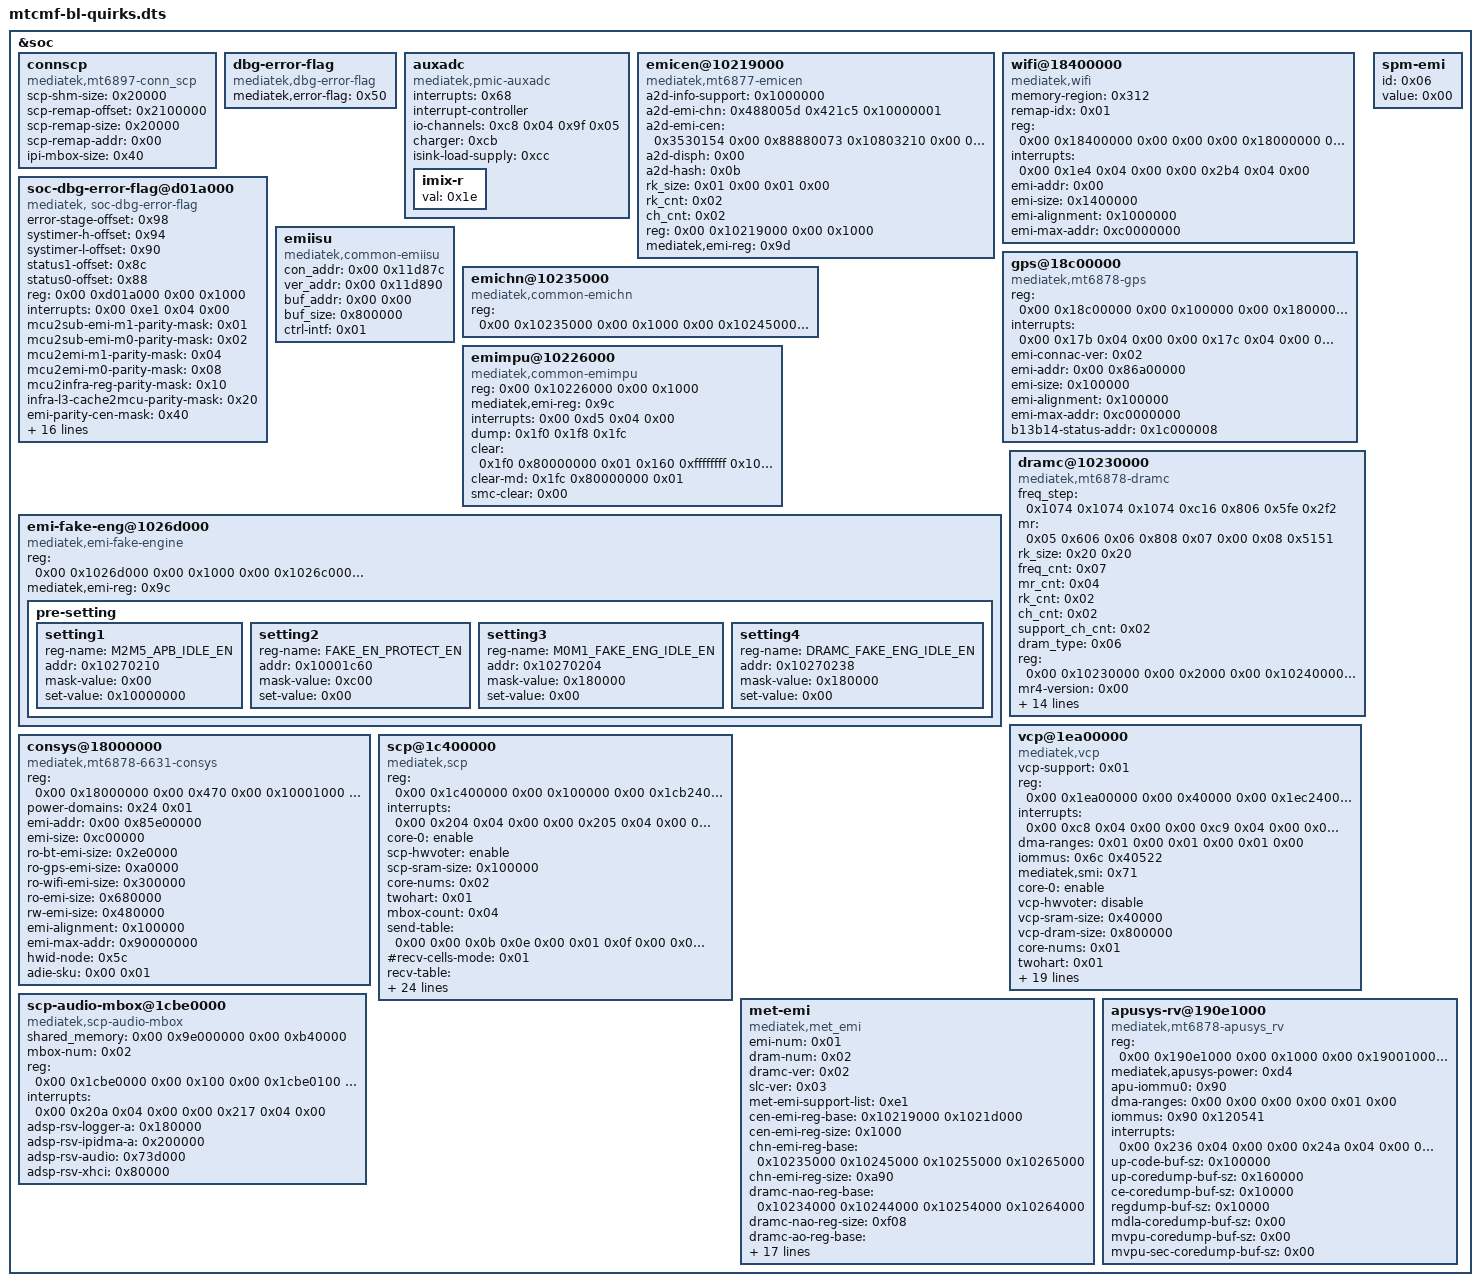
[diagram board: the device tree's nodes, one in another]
&soc {
        			connscp {
				compatible = "mediatek,mt6897-conn_scp";
				scp-shm-size = <0x20000>;
				scp-remap-offset = <0x2100000>;
				scp-remap-size = <0x20000>;
				scp-remap-addr = <0x00>;
				ipi-mbox-size = <0x40>;
				phandle = <0x26f>;
			};
			
			dbg-error-flag {
				compatible = "mediatek,dbg-error-flag";
				mediatek,error-flag = <0x50>;
			};
			
			auxadc {
				compatible = "mediatek,pmic-auxadc\0mediatek,mt6375-auxadc";
				interrupts = <0x68>;
				interrupt-controller;
				#interrupt-cells = <0x01>;
				#io-channel-cells = <0x01>;
				io-channels = <0xc8 0x04 0x9f 0x05>;
				io-channel-names = "chg_vbat\0auxadc_vbat";
				charger = <0xcb>;
				isink-load-supply = <0xcc>;
				phandle = <0x9f>;
				
				imix-r {
					val = <0x1e>;
				};
			};
			
			emicen@10219000 {
				a2d-info-support = <0x1000000>;
				a2d-emi-chn = <0x488005d 0x421c5 0x10000001>;
				a2d-emi-cen = <0x3530154 0x00 0x88880073 0x10803210 0x00 0x00>;
				a2d-disph = <0x00>;
				a2d-hash = <0x0b>;
				rk_size = <0x01 0x00 0x01 0x00>;
				rk_cnt = <0x02>;
				ch_cnt = <0x02>;
				compatible = "mediatek,mt6877-emicen";
				reg = <0x00 0x10219000 0x00 0x1000>;
				mediatek,emi-reg = <0x9d>;
				phandle = <0x9c>;
			};
			
			wifi@18400000 {
				memory-region = <0x312>;
				compatible = "mediatek,wifi";
				remap-idx = <0x01>;
				reg = <0x00 0x18400000 0x00 0x00 0x00 0x18000000 0x00 0x700000>;
				interrupts = <0x00 0x1e4 0x04 0x00 0x00 0x2b4 0x04 0x00>;
				emi-addr = <0x00>;
				emi-size = <0x1400000>;
				emi-alignment = <0x1000000>;
				emi-max-addr = <0xc0000000>;
				phandle = <0x28e>;
			};
			
			soc-dbg-error-flag@d01a000 {
				error-stage-offset = <0x98>;
				systimer-h-offset = <0x94>;
				systimer-l-offset = <0x90>;
				status1-offset = <0x8c>;
				status0-offset = <0x88>;
				compatible = "mediatek, soc-dbg-error-flag";
				reg = <0x00 0xd01a000 0x00 0x1000>;
				interrupts = <0x00 0xe1 0x04 0x00>;
				interrupt-names = "dbg-error-flag";
				mcu2sub-emi-m1-parity-mask = <0x01>;
				mcu2sub-emi-m0-parity-mask = <0x02>;
				mcu2emi-m1-parity-mask = <0x04>;
				mcu2emi-m0-parity-mask = <0x08>;
				mcu2infra-reg-parity-mask = <0x10>;
				infra-l3-cache2mcu-parity-mask = <0x20>;
				emi-parity-cen-mask = <0x40>;
				emi-parity-sub-cen-mask = <0x80>;
				emi-parity-chan1-mask = <0x100>;
				emi-parity-chan2-mask = <0x200>;
				emi-parity-chan3-mask = <0x400>;
				emi-parity-chan4-mask = <0x800>;
				dramc-error-flag-ch-a-mask = <0x1000>;
				dramc-error-flag-ch-b-mask = <0x2000>;
				dramc-error-flag-ch-c-mask = <0x4000>;
				dramc-error-flag-ch-d-mask = <0x8000>;
				ap-tracker-timeout-mask = <0x10000>;
				infra-tracker-timeout-mask = <0x20000>;
				infra-lastbus-timeout-mask = <0x1000000>;
				peri-lastbus-timeout-mask = <0x2000000>;
				dram-md32-wdt-event-ch-a-mask = <0x8000000>;
				dram-md32-wdt-event-ch-b-mask = <0x10000000>;
				dram-md32-wdt-event-ch-c-mask = <0x20000000>;
				phandle = <0x50>;
			};
			
			emiisu {
				con_addr = <0x00 0x11d87c>;
				ver_addr = <0x00 0x11d890>;
				buf_addr = <0x00 0x00>;
				buf_size = <0x800000>;
				compatible = "mediatek,common-emiisu";
				ctrl-intf = <0x01>;
			};
			gps@18c00000 {
				compatible = "mediatek,mt6878-gps";
				reg = <0x00 0x18c00000 0x00 0x100000 0x00 0x18000000 0x00 0x100000 0x00 0x1c000000 0x00 0x04 0x00 0x1c013058 0x00 0x04 0x00 0x1c013060 0x00 0x04 0x00 0x1c0130f8 0x00 0x28>;
				reg-names = "conn_gps_base\0conn_infra_base\0status_dummy_cr\0tia2_gps_on\0tia2_gps_rc_sel\0tia2_gps_debug";
				interrupts = <0x00 0x17b 0x04 0x00 0x00 0x17c 0x04 0x00 0x00 0x17d 0x04 0x00 0x00 0x17e 0x04 0x00 0x00 0x17f 0x04 0x00 0x00 0x185 0x04 0x00 0x00 0x81 0x04 0x00>;
				emi-connac-ver = <0x02>;
				emi-addr = <0x00 0x86a00000>;
				emi-size = <0x100000>;
				emi-alignment = <0x100000>;
				emi-max-addr = <0xc0000000>;
				b13b14-status-addr = <0x1c000008>;
				phandle = <0x249>;
			};
			
			
			emichn@10235000 {
				compatible = "mediatek,common-emichn";
				reg = <0x00 0x10235000 0x00 0x1000 0x00 0x10245000 0x00 0x1000>;
				phandle = <0x9d>;
			};
			
			emimpu@10226000 {
				compatible = "mediatek,common-emimpu";
				reg = <0x00 0x10226000 0x00 0x1000>;
				mediatek,emi-reg = <0x9c>;
				interrupts = <0x00 0xd5 0x04 0x00>;
				dump = <0x1f0 0x1f8 0x1fc>;
				clear = <0x1f0 0x80000000 0x01 0x160 0xffffffff 0x10 0x200 0x03 0x10>;
				clear-md = <0x1fc 0x80000000 0x01>;
				smc-clear = <0x00>;
				phandle = <0x1ca>;
			};
			emi-fake-eng@1026d000 {
				compatible = "mediatek,emi-fake-engine";
				reg = <0x00 0x1026d000 0x00 0x1000 0x00 0x1026c000 0x00 0x1000>;
				mediatek,emi-reg = <0x9c>;
				
				pre-setting {
					
					setting1 {
						reg-name = "M2M5_APB_IDLE_EN";
						addr = <0x10270210>;
						mask-value = <0x00>;
						set-value = <0x10000000>;
					};
					
					setting2 {
						reg-name = "FAKE_EN_PROTECT_EN";
						addr = <0x10001c60>;
						mask-value = <0xc00>;
						set-value = <0x00>;
					};
					
					setting3 {
						reg-name = "M0M1_FAKE_ENG_IDLE_EN";
						addr = <0x10270204>;
						mask-value = <0x180000>;
						set-value = <0x00>;
					};
					
					setting4 {
						reg-name = "DRAMC_FAKE_ENG_IDLE_EN";
						addr = <0x10270238>;
						mask-value = <0x180000>;
						set-value = <0x00>;
					};
				};
			};
			
			dramc@10230000 {
				freq_step = <0x1074 0x1074 0x1074 0xc16 0x806 0x5fe 0x2f2>;
				mr = <0x05 0x606 0x06 0x808 0x07 0x00 0x08 0x5151>;
				rk_size = <0x20 0x20>;
				freq_cnt = <0x07>;
				mr_cnt = <0x04>;
				rk_cnt = <0x02>;
				ch_cnt = <0x02>;
				support_ch_cnt = <0x02>;
				dram_type = <0x06>;
				compatible = "mediatek,mt6878-dramc\0mediatek,common-dramc";
				reg = <0x00 0x10230000 0x00 0x2000 0x00 0x10240000 0x00 0x2000 0x00 0x10234000 0x00 0x1000 0x00 0x10244000 0x00 0x1000 0x00 0x10238000 0x00 0x2000 0x00 0x10248000 0x00 0x2000 0x00 0x10236000 0x00 0x2000 0x00 0x10246000 0x00 0x2000 0x00 0x10006000 0x00 0x1000>;
				mr4-version = <0x00>;
				mr4-rg = <0x90 0xffff 0x00>;
				fmeter-version = <0x03>;
				use-real-freq = <0x01>;
				crystal-freq = <0x1a>;
				pll-id = <0xe98 0x2000000 0x19>;
				shu-lv = <0xe98 0xc000 0x0e>;
				shu-of = <0x700>;
				sdmpcw = <0x908 0x7fff8 0x03 0x928 0x7fff8 0x03>;
				posdiv = <0x90c 0x3800 0x0b 0x92c 0x3800 0x0b>;
				fbksel = <0x910 0x40 0x06 0x910 0x40 0x06>;
				dqsopen = <0xd94 0x4000000 0x1a 0xd94 0x4000000 0x1a>;
				async-ca = <0xd08 0x01 0x00 0xd08 0x01 0x00>;
				dq-ser-mode = <0xdc4 0x18 0x03 0xdc4 0x18 0x03>;
				phandle = <0x201>;
			};
			
			vcp@1ea00000 {
				#address-cells = <0x02>;
				#size-cells = <0x02>;
				compatible = "mediatek,vcp";
				vcp-support = <0x01>;
				status = "okay";
				reg = <0x00 0x1ea00000 0x00 0x40000 0x00 0x1ec24000 0x00 0x1000 0x00 0x1ec30000 0x00 0x1000 0x00 0x1ec32000 0x00 0x1000 0x00 0x1ec37000 0x00 0x1000 0x00 0x1ec40000 0x00 0x1000 0x00 0x1ec51000 0x00 0x1000 0x00 0x1ec52000 0x00 0x1000 0x00 0x1ec60000 0x00 0x40000 0x00 0x1eca5000 0x00 0x04 0x00 0x1e820000 0x00 0x04 0x00 0x1ecfb000 0x00 0x100 0x00 0x1ecfb100 0x00 0x04 0x00 0x1ecfb10c 0x00 0x04 0x00 0x1eca5020 0x00 0x04 0x00 0x1ecfc000 0x00 0x100 0x00 0x1ecfc100 0x00 0x04 0x00 0x1ecfc10c 0x00 0x04 0x00 0x1eca5024 0x00 0x04 0x00 0x1ecfd000 0x00 0x100 0x00 0x1ecfd100 0x00 0x04 0x00 0x1ecfd10c 0x00 0x04 0x00 0x1eca5028 0x00 0x04 0x00 0x1ecfe000 0x00 0x100 0x00 0x1ecfe100 0x00 0x04 0x00 0x1ecfe10c 0x00 0x04 0x00 0x1eca502c 0x00 0x04 0x00 0x1ecff000 0x00 0x100 0x00 0x1ecff100 0x00 0x04 0x00 0x1ecff10c 0x00 0x04 0x00 0x1eca5030 0x00 0x04>;
				reg-names = "vcp_sram_base\0vcp_cfgreg\0vcp_cfgreg_core0\0vcp_intc_core0\0vcp_pwr_ctl\0vcp_cfgreg_core1\0vcp_bus_debug\0vcp_bus_tracker\0vcp_l1creg\0vcp_cfgreg_sec\0vcp_cfgreg_mmu\0mbox0_base\0mbox0_set\0mbox0_clr\0mbox0_init\0mbox1_base\0mbox1_set\0mbox1_clr\0mbox1_init\0mbox2_base\0mbox2_set\0mbox2_clr\0mbox2_init\0mbox3_base\0mbox3_set\0mbox3_clr\0mbox3_init\0mbox4_base\0mbox4_set\0mbox4_clr\0mbox4_init";
				interrupts = <0x00 0xc8 0x04 0x00 0x00 0xc9 0x04 0x00 0x00 0xca 0x04 0x00 0x00 0xcb 0x04 0x00 0x00 0xcc 0x04 0x00 0x00 0xcd 0x04 0x00 0x00 0xce 0x04 0x00>;
				interrupt-names = "wdt\0reserved\0mbox0\0mbox1\0mbox2\0mbox3\0mbox4";
				dma-ranges = <0x01 0x00 0x01 0x00 0x01 0x00>;
				iommus = <0x6c 0x40522>;
				mediatek,smi = <0x71>;
				core-0 = "enable";
				vcp-hwvoter = "disable";
				vcp-sram-size = <0x40000>;
				vcp-dram-size = <0x800000>;
				core-nums = <0x01>;
				twohart = <0x01>;
				fmeter-ck = <0x07>;
				fmeter-type = <0x02>;
				mbox-count = <0x05>;
				vcp-ee-enable = <0x04>;
				bus-debug-num-ports = <0x0d>;
				send-table = <0x00 0x00 0x12 0x02 0x01 0x02 0x03 0x01 0x02 0x09 0x01 0x02 0x0b 0x01 0x02 0x0d 0x01 0x02 0x0f 0x01 0x04 0x10 0x02 0x12 0x12 0x02 0x04 0x14 0x03 0x02 0x15 0x03 0x02 0x16 0x03 0x06 0x17 0x03 0x02 0x1c 0x04 0x04>;
				recv-table = <0x01 0x00 0x12 0x00 0x02 0x01 0x01 0x01 0x04 0x01 0x0a 0x00 0x05 0x01 0x01 0x00 0x06 0x01 0x02 0x00 0x0a 0x01 0x02 0x00 0x0c 0x01 0x02 0x00 0x0e 0x01 0x02 0x00 0x0f 0x01 0x04 0x01 0x11 0x02 0x12 0x00 0x13 0x02 0x04 0x00 0x14 0x03 0x01 0x01 0x18 0x03 0x0a 0x00 0x19 0x03 0x06 0x00 0x1a 0x03 0x01 0x00 0x1b 0x03 0x02 0x00 0x1d 0x04 0x04 0x00>;
				vcp-secure-dump = <0x01>;
				vcp-secure-dump-size = <0x200000>;
				vcp-secure-dump-offset = <0x600000>;
				vcp-sec-dump-key = "mediatek,me_vcp_reserved";
				memorydump = <0x40000 0x20000 0x3f00 0x400 0x160000>;
				vcp-mem-tbl = <0x00 0x78000 0x01 0x12000 0x02 0x180000 0x03 0x400 0x04 0x400 0x05 0x400 0x06 0x400 0x07 0x100000 0x08 0x1000 0x09 0x1000 0x0a 0x00>;
				power-domains = <0x24 0x14>;
				clocks = <0x43 0x06 0x43 0x5c 0x43 0xae>;
				clock-names = "mmup-sel\0mmup-clk\0mmup-26m";
				phandle = <0x254>;
			};
			
			consys@18000000 {
				compatible = "mediatek,mt6878-6631-consys";
				#thermal-sensor-cells = <0x00>;
				reg = <0x00 0x18000000 0x00 0x470 0x00 0x10001000 0x00 0xee4 0x00 0x10005000 0x00 0xa7c 0x00 0x11ec0000 0x00 0xa04 0x00 0x18001000 0x00 0x658 0x00 0x18003000 0x00 0x204 0x00 0x1800e000 0x00 0x118 0x00 0x18011000 0x00 0x138 0x00 0x18012000 0x00 0x98 0x00 0x18020000 0x00 0x4c 0x00 0x18023000 0x00 0xe28 0x00 0x1803b000 0x00 0x18 0x00 0x18040000 0x00 0x2c 0x00 0x18041000 0x00 0x140 0x00 0x18042000 0x00 0x324 0x00 0x18046000 0x00 0x324 0x00 0x1804b000 0x00 0x414 0x00 0x1804d000 0x00 0x41c 0x00 0x1804f000 0x00 0x148 0x00 0x18053800 0x00 0x1000 0x00 0x18060000 0x00 0xbf8 0x00 0x18070000 0x00 0x8004 0x00 0x1c001000 0x00 0xfd0 0x00 0x1c00a000 0x00 0x51c 0x00 0x1803c000 0x00 0x34 0x00 0x1803e000 0x00 0x34>;
				power-domains = <0x24 0x01>;
				emi-addr = <0x00 0x85e00000>;
				emi-size = <0xc00000>;
				ro-bt-emi-size = <0x2e0000>;
				ro-gps-emi-size = <0xa0000>;
				ro-wifi-emi-size = <0x300000>;
				ro-emi-size = <0x680000>;
				rw-emi-size = <0x480000>;
				emi-alignment = <0x100000>;
				emi-max-addr = <0x90000000>;
				hwid-node = <0x5c>;
				adie-sku = <0x00 0x01>;
				phandle = <0x59>;
			};
			
			
			scp@1c400000 {
				compatible = "mediatek,scp";
				status = "okay";
				reg = <0x00 0x1c400000 0x00 0x100000 0x00 0x1cb24000 0x00 0x1000 0x00 0x1cb21000 0x00 0x1000 0x00 0x1cb30000 0x00 0x1000 0x00 0x1cb40000 0x00 0x1000 0x00 0x1cb80000 0x00 0x1000 0x00 0x1cb60000 0x00 0x20000 0x00 0x1cb2a000 0x00 0x04 0x00 0x1cba0000 0x00 0x100 0x00 0x1cba0100 0x00 0x04 0x00 0x1cba010c 0x00 0x04 0x00 0x1cb2a020 0x00 0x04 0x00 0x1cbb0000 0x00 0x100 0x00 0x1cbb0100 0x00 0x04 0x00 0x1cbb010c 0x00 0x04 0x00 0x1cb2a024 0x00 0x04 0x00 0x1cbc0000 0x00 0x100 0x00 0x1cbc0100 0x00 0x04 0x00 0x1cbc010c 0x00 0x04 0x00 0x1cb2a028 0x00 0x04 0x00 0x1cbd0000 0x00 0x100 0x00 0x1cbd0100 0x00 0x04 0x00 0x1cbd010c 0x00 0x04 0x00 0x1cb2a02c 0x00 0x04 0x00 0x1cbe0000 0x00 0x100 0x00 0x1cbe0100 0x00 0x04 0x00 0x1cbe010c 0x00 0x04 0x00 0x1cb2a030 0x00 0x04 0x00 0x1cb50000 0x00 0x1000>;
				reg-names = "scp_sram_base\0scp_cfgreg\0scp_clkreg\0scp_cfgreg_core0\0scp_cfgreg_core1\0scp_bus_tracker\0scp_l1creg\0scp_cfgreg_sec\0mbox0_base\0mbox0_set\0mbox0_clr\0mbox0_init\0mbox1_base\0mbox1_set\0mbox1_clr\0mbox1_init\0mbox2_base\0mbox2_set\0mbox2_clr\0mbox2_init\0mbox3_base\0mbox3_set\0mbox3_clr\0mbox3_init\0mbox4_base\0mbox4_set\0mbox4_clr\0mbox4_init\0scp_cfgreg_ap";
				interrupts = <0x00 0x204 0x04 0x00 0x00 0x205 0x04 0x00 0x00 0x206 0x04 0x00 0x00 0x207 0x04 0x00 0x00 0x208 0x04 0x00 0x00 0x209 0x04 0x00 0x00 0x20a 0x04 0x00>;
				interrupt-names = "ipc0\0ipc1\0mbox0\0mbox1\0mbox2\0mbox3\0mbox4";
				core-0 = "enable";
				scp-hwvoter = "enable";
				scp-sram-size = <0x100000>;
				core-nums = <0x02>;
				twohart = <0x01>;
				mbox-count = <0x04>;
				send-table = <0x00 0x00 0x0b 0x0e 0x00 0x01 0x0f 0x00 0x02 0x10 0x00 0x01 0x11 0x01 0x06 0x12 0x01 0x02 0x2e 0x01 0x01 0x1d 0x01 0x10 0x1f 0x01 0x07 0x04 0x02 0x01 0x05 0x02 0x02 0x06 0x02 0x01 0x21 0x02 0x10 0x03 0x03 0x04 0x25 0x03 0x01 0x1a 0x03 0x09 0x23 0x03 0x02 0x27 0x03 0x04 0x2b 0x03 0x04 0x2d 0x03 0x01>;
				#recv-cells-mode = <0x01>;
				recv-table = <0x01 0x00 0x02 0x00 0x00 0x00 0x00 0x02 0x00 0x1a 0x00 0x00 0x00 0x00 0x24 0x00 0x01 0x00 0x00 0x00 0x00 0x0f 0x00 0x01 0x01 0x00 0x00 0x00 0x14 0x01 0x0a 0x00 0x00 0x00 0x00 0x15 0x01 0x06 0x00 0x00 0x00 0x00 0x16 0x01 0x01 0x00 0x00 0x00 0x00 0x1e 0x01 0x02 0x00 0x00 0x00 0x00 0x20 0x01 0x07 0x00 0x00 0x00 0x00 0x05 0x02 0x01 0x01 0x00 0x00 0x00 0x08 0x02 0x0a 0x00 0x00 0x00 0x00 0x22 0x02 0x10 0x00 0x00 0x00 0x00 0x07 0x03 0x02 0x00 0x00 0x00 0x00 0x26 0x03 0x01 0x00 0x00 0x00 0x00 0x1c 0x03 0x05 0x00 0x00 0x00 0x00 0x1b 0x03 0x02 0x00 0x00 0x00 0x00 0x23 0x03 0x04 0x01 0x00 0x00 0x00 0x28 0x03 0x04 0x00 0x00 0x00 0x00 0x2c 0x03 0x04 0x00 0x00 0x00 0x00>;
				scp-feature-tbl = <0x00 0x28 0x00 0x01 0x00 0x00 0x02 0x1a 0x00 0x03 0x00 0x00 0x04 0xc8 0x00 0x05 0x00 0x00 0x06 0x87 0x00 0x07 0x0a 0x00 0x08 0x50 0x00 0x09 0x2b 0x00 0x0a 0x16 0x00 0x0b 0x14 0x00 0x0c 0x64 0x00 0x0d 0xc8 0x00>;
				scp-dram-region = "enable";
				scp-protect = "enable";
				secure-dump = "enable";
				secure-dump-size = <0xe28000>;
				scp-pm-notify = "enable";
				scp-thermal-wq = "disable";
				scp-low-pwr-dbg = "enable";
				scp-cfgreg-ap-en = "enable";
				scp-ipc-wa = "disable";
				scp-mbrain = "enable";
				scp-bus-tracker-ver = <0x02>;
				scp-mem-key = "mediatek,reserve-memory-scp_share";
				scp-mem-tbl = <0x00 0x00 0x00 0x01 0xca700 0x00 0x02 0x100000 0x00 0x03 0x180000 0x00 0x05 0xa000 0x00 0x07 0x1a000 0x00 0x08 0x10000 0x00 0x09 0x1000 0x00 0x0a 0x2000 0x00 0x0b 0x100 0x00 0x0c 0x100 0x00 0x13 0x200 0x00>;
				memorydump = <0x100000 0xc4000 0x3c00 0x400 0xc60000>;
				scp-resource-dump = "disable";
				scp-supply-num = <0x03>;
				scp-resource-reg-dump-cell = <0x02>;
				scp-resource-reg-dump = <0x1c001818 0x04 0x1c00192c 0x04>;
				phandle = <0x276>;
			};
			
			scp-audio-mbox@1cbe0000 {
				shared_memory = <0x00 0x9e000000 0x00 0xb40000>;
				compatible = "mediatek,scp-audio-mbox";
				status = "okay";
				mbox-num = <0x02>;
				reg = <0x00 0x1cbe0000 0x00 0x100 0x00 0x1cbe0100 0x00 0x04 0x00 0x1cbe010c 0x00 0x04 0x00 0x1cbf0000 0x00 0x100 0x00 0x1cbf0100 0x00 0x04 0x00 0x1cbf010c 0x00 0x04>;
				reg-names = "mbox0_base\0mbox0_set\0mbox0_clr\0mbox1_base\0mbox1_set\0mbox1_clr";
				interrupts = <0x00 0x20a 0x04 0x00 0x00 0x217 0x04 0x00>;
				interrupt-names = "mbox0\0mbox1";
				adsp-rsv-logger-a = <0x180000>;
				adsp-rsv-ipidma-a = <0x200000>;
				adsp-rsv-audio = <0x73d000>;
				adsp-rsv-xhci = <0x80000>;
				phandle = <0x277>;
			};
			
			spm-emi {
				id = <0x06>;
				value = <0x00>;
				phandle = <0x117>;
			};
			
			met-emi {
				compatible = "mediatek,met_emi";
				emi-num = <0x01>;
				dram-num = <0x02>;
				dramc-ver = <0x02>;
				slc-ver = <0x03>;
				met-emi-support-list = <0xe1>;
				cen-emi-reg-base = <0x10219000 0x1021d000>;
				cen-emi-reg-size = <0x1000>;
				chn-emi-reg-base = <0x10235000 0x10245000 0x10255000 0x10265000>;
				chn-emi-reg-size = <0xa90>;
				dramc-nao-reg-base = <0x10234000 0x10244000 0x10254000 0x10264000>;
				dramc-nao-reg-size = <0xf08>;
				dramc-ao-reg-base = <0x10230000 0x10240000 0x10250000 0x10260000>;
				dramc-ao-reg-size = <0x2000>;
				dramc-ao-bus-mon1 = <0x118>;
				ddrphy-ao-reg-base = <0x10238000 0x10248000 0x10258000 0x10268000>;
				ddrphy-ao-reg-size = <0x1650>;
				ddrphy-ao-misc-cg-ctrl0 = <0x00>;
				ddrphy-ao-misc-cg-ctrl2 = <0xad4>;
				dram-freq-default = <0x1900>;
				ddr-ratio-default = <0x08>;
				dram-type-default = <0x08>;
				apmixedsys-reg-base = <0x1000c000>;
				apmixedsys-reg-size = <0x410>;
				slc-pmu-reg-base = <0x10342000 0x10343000>;
				slc-pmu-reg-size = <0x1000>;
				slc-pmu-2nd-reg-base = <0x10359000 0x1035c000>;
				slc-pmu-2nd-reg-size = <0x1000>;
				phandle = <0x289>;
			};
			
			apusys-rv@190e1000 {
				#address-cells = <0x02>;
				#size-cells = <0x02>;
				compatible = "mediatek,mt6878-apusys_rv";
				status = "okay";
				reg = <0x00 0x190e1000 0x00 0x1000 0x00 0x19001000 0x00 0x1000 0x00 0x19002000 0x00 0x10 0x00 0x1903c000 0x00 0x8000 0x00 0x19050000 0x00 0x10000 0x00 0x190f2000 0x00 0x1000 0x00 0x1d000000 0x00 0x20000 0x00 0xd2a0000 0x00 0x10000>;
				reg-names = "apu_mbox\0md32_sysctrl\0apu_wdt\0apu_sctrl_reviser\0md32_cache_dump\0apu_ao_ctl\0md32_tcm\0md32_debug_apb";
				mediatek,apusys-power = <0xd4>;
				apu-iommu0 = <0x90>;
				dma-ranges = <0x00 0x00 0x00 0x00 0x01 0x00>;
				iommus = <0x90 0x120541>;
				interrupts = <0x00 0x236 0x04 0x00 0x00 0x24a 0x04 0x00 0x00 0x24b 0x04 0x00 0x00 0x254 0x04 0x00>;
				interrupt-names = "apu_wdt\0mbox0_irq\0mbox1_irq\0ce_exp_irq";
				up-code-buf-sz = <0x100000>;
				up-coredump-buf-sz = <0x160000>;
				ce-coredump-buf-sz = <0x10000>;
				regdump-buf-sz = <0x10000>;
				mdla-coredump-buf-sz = <0x00>;
				mvpu-coredump-buf-sz = <0x00>;
				mvpu-sec-coredump-buf-sz = <0x00>;
				phandle = <0xd6>;
			};
};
